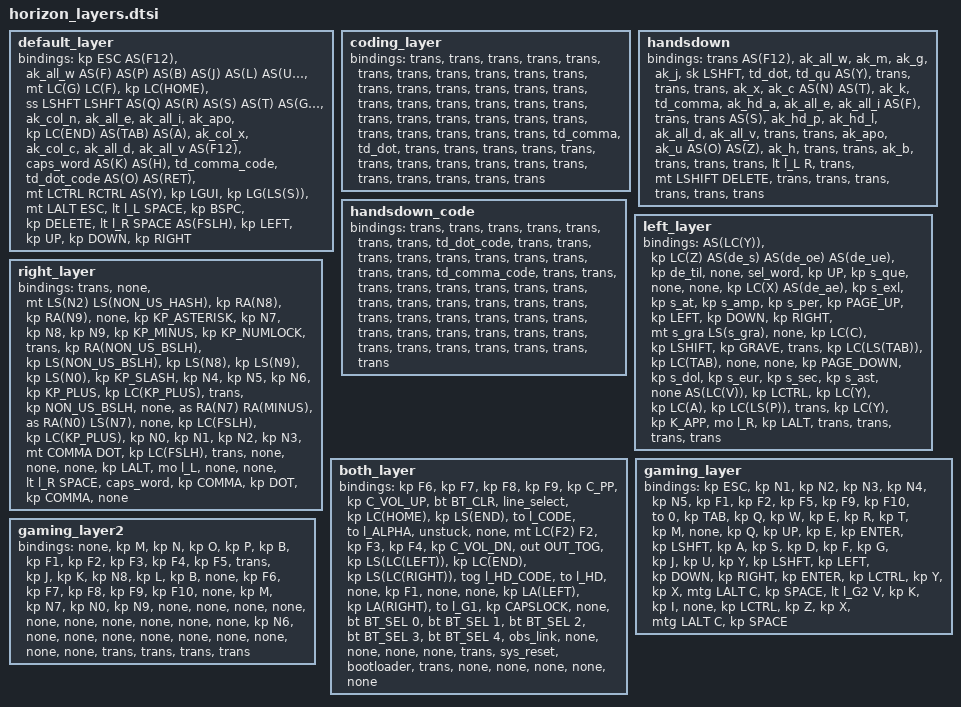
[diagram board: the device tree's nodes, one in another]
default_layer {
    bindings = <
&kp ESC         AS(F12) &ak_all_w AS(F)         AS(P)         AS(B)                                   AS(J)         AS(L)     AS(U)     AS(Z)     &mt LC(G) LC(F) &kp LC(HOME)
&ss LSHFT LSHFT AS(Q)   AS(R)     AS(S)         AS(T)         AS(G)                                   AS(M)         &ak_col_n &ak_all_e &ak_all_i  &ak_apo         &kp LC(END)
AS(TAB)         AS(A)   &ak_col_x     &ak_col_c         &ak_all_d &ak_all_v   AS(F12) &caps_word      AS(K)         AS(H)     &td_comma_code &td_dot_code   AS(O)           AS(RET)
&mt LCTRL RCTRL   AS(Y)   &kp LGUI  &kp LG(LS(S)) &mt LALT ESC  &lt l_L SPACE  &kp BSPC     &kp DELETE  &lt l_R SPACE AS(FSLH)  &kp LEFT  &kp UP    &kp DOWN        &kp RIGHT
    >;
};

coding_layer {
    bindings = <
&trans &trans &trans &trans &trans &trans                 &trans &trans &trans          &trans  &trans &trans
&trans &trans &trans &trans &trans &trans                 &trans &trans &trans          &trans  &trans &trans
&trans &trans &trans &trans &trans &trans  &trans  &trans &trans &trans &td_comma &td_dot &trans &trans
&trans &trans &trans &trans &trans &trans  &trans  &trans &trans &trans &trans           &trans  &trans &trans
    >;
};

 handsdown {
    bindings = <    
&trans  AS(F12) &ak_all_w  &ak_m  &ak_g     &ak_j                              &sk LSHFT &td_dot  &td_qu    AS(Y)     &trans   &trans
&trans  &ak_x   &ak_c      AS(N)  AS(T)     &ak_k                              &td_comma &ak_hd_a &ak_all_e &ak_all_i AS(F)    &trans
&trans  AS(S)   &ak_hd_p      &ak_hd_l  &ak_all_d  &ak_all_v   &trans    &trans  &ak_apo &ak_u    AS(O)     AS(Z)     &ak_h   &trans
&trans  &ak_b   &trans     &trans &trans    &lt l_L R   &trans    &mt LSHIFT DELETE &trans  &trans &trans  &trans  &trans    &trans
    >;
};

handsdown_code {
       bindings = <
&trans  &trans  &trans  &trans  &trans  &trans                  &trans          &td_dot_code &trans &trans  &trans  &trans
&trans  &trans  &trans  &trans  &trans  &trans                  &td_comma_code  &trans  &trans &trans  &trans  &trans
&trans  &trans  &trans  &trans  &trans  &trans  &trans  &trans  &trans          &trans  &trans &trans  &trans  &trans
&trans  &trans  &trans  &trans  &trans  &trans  &trans  &trans  &trans          &trans  &trans &trans  &trans  &trans
    >;
};


left_layer {
    bindings = <
AS(LC(Y))   &kp LC(Z)  AS(de_s)  AS(de_oe)  AS(de_ue)       &kp de_til                    &none          &sel_word  &kp UP    &kp s_que    &none                &none
&kp LC(X)   AS(de_ae)  &kp s_exl &kp s_at   &kp s_amp       &kp s_per                     &kp PAGE_UP    &kp LEFT   &kp DOWN  &kp RIGHT    &mt s_gra LS(s_gra)  &none
&kp LC(C)   &kp LSHIFT &kp GRAVE &trans     &kp LC(LS(TAB)) &kp LC(TAB)  &none  &none     &kp PAGE_DOWN  &kp s_dol  &kp s_eur &kp s_sec      &kp s_ast          &none
AS(LC(V))   &kp LCTRL  &kp LC(Y)   &kp LC(A)     &kp LC(LS(P))   &trans   &kp LC(Y)  &kp K_APP &mo l_R        &kp LALT   &trans    &trans       &trans            &trans                                                                                 
    >;
};



right_layer {
    bindings = <
&trans   &none               &mt LS(N2) LS(NON_US_HASH) &kp RA(N8)           &kp RA(N9)   &none                                    &kp KP_ASTERISK  &kp N7     &kp N8    &kp N9  &kp KP_MINUS   &kp KP_NUMLOCK
&trans   &kp RA(NON_US_BSLH) &kp LS(NON_US_BSLH)        &kp LS(N8)           &kp LS(N9)   &kp LS(N0)                               &kp KP_SLASH     &kp N4     &kp N5    &kp N6  &kp KP_PLUS    &kp LC(KP_PLUS)
&trans   &kp NON_US_BSLH     &none                 &as RA(N7) RA(MINUS) &as RA(N0) LS(N7) &none      &kp LC(FSLH) &kp LC(KP_PLUS)  &kp N0           &kp N1     &kp N2    &kp N3  &mt COMMA DOT  &kp LC(FSLH)
&trans   &none               &none                      &none                &kp LALT     &mo l_L    &none         &none           &lt l_R SPACE    &caps_word &kp COMMA &kp DOT &kp COMMA       &none
    >;
};

both_layer {
    bindings = <
&kp F6    &kp F7 &kp F8         &kp F9  &kp C_PP     &kp C_VOL_UP                          &bt BT_CLR   &line_select     &kp LC(HOME)  &kp LS(END)       &to l_CODE   &to l_ALPHA
&unstuck     &none  &mt LC(F2) F2  &kp F3  &kp F4       &kp C_VOL_DN                       &out OUT_TOG &kp LS(LC(LEFT)) &kp LC(END)   &kp LS(LC(RIGHT)) &tog l_HD_CODE &to l_HD
&none     &kp F1 &none          &none   &kp LA(LEFT) &kp LA(RIGHT) &to l_G1   &kp CAPSLOCK &none        &bt BT_SEL 0     &bt BT_SEL 1  &bt BT_SEL 2      &bt BT_SEL 3 &bt BT_SEL 4
&obs_link &none  &none          &none   &none        &trans        &sys_reset &bootloader  &trans       &none            &none         &none             &none        &none
    >;
};

gaming_layer {
    bindings = <
&kp ESC   &kp N1  &kp N2   &kp N3     &kp N4     &kp N5                  &kp F1 &kp F2    &kp F5   &kp F9   &kp F10     &to 0
&kp TAB   &kp Q   &kp W    &kp E      &kp R      &kp T                   &kp M  &none     &kp Q    &kp UP   &kp E       &kp ENTER 
&kp LSHFT &kp A   &kp S    &kp D      &kp F      &kp G       &kp J &kp U &kp Y  &kp LSHFT &kp LEFT &kp DOWN &kp RIGHT   &kp ENTER
&kp LCTRL &kp Y   &kp X    &mtg LALT C &kp SPACE &lt l_G2 V  &kp K &kp I &none  &kp LCTRL &kp Z    &kp X    &mtg LALT C &kp SPACE
    >;
};

gaming_layer2 {
    bindings = <
&none  &kp M  &kp N  &kp O  &kp P &kp B             &kp F1 &kp F2 &kp F3  &kp F4  &kp F5  &trans
&kp J  &kp K  &kp N8 &kp L  &kp B &none             &kp F6 &kp F7 &kp F8  &kp F9  &kp F10 &none
&kp M  &kp N7 &kp N0 &kp N9 &none &none &none &none &none  &none  &none   &none   &none   &none
&kp N6 &none  &none  &none  &none &none &none &none &none  &none  &trans  &trans  &trans  &trans                                  
    >;
}; 

